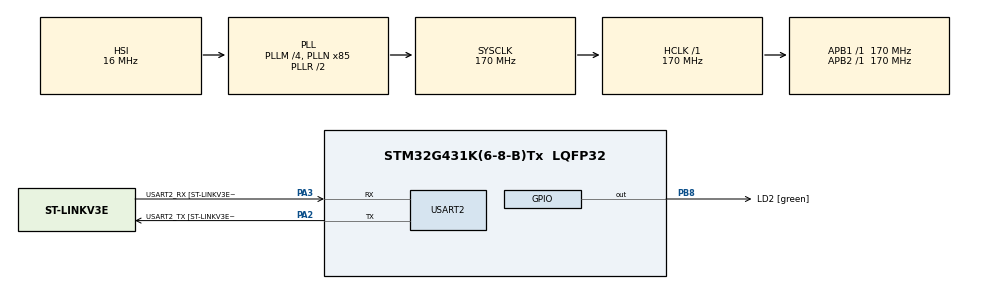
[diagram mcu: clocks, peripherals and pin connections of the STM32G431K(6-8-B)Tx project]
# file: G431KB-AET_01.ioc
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Mcu.Family=STM32G4
Mcu.Name=STM32G431K(6-8-B)Tx
Mcu.Package=LQFP32
NVIC.PriorityGroup=NVIC_PRIORITYGROUP_4
PA13.GPIO_Label=T_SWDIO
PA13.Mode=Serial_Wire
PA13.Signal=SYS_JTMS-SWDIO
PA14.GPIO_Label=T_SWCLK
PA14.Mode=Serial_Wire
PA14.Signal=SYS_JTCK-SWCLK
PA2.GPIO_Label=USART2_TX [ST-LINKV3E_VCP_RX]
PA2.Mode=Asynchronous
PA2.Signal=USART2_TX
PA3.GPIO_Label=USART2_RX [ST-LINKV3E_VCP_TX]
PA3.Mode=Asynchronous
PA3.Signal=USART2_RX
PB3.GPIO_Label=T_SWO
PB3.Signal=SYS_JTDO-SWO
PB8-BOOT0.GPIO_Label=LD2 [green]
PB8-BOOT0.Signal=GPIO_Output
ProjectManager.HeapSize=0x200
ProjectManager.StackSize=0x400
ProjectManager.TargetToolchain=STM32CubeIDE
RCC.ADC12Freq_Value=170000000
RCC.AHBFreq_Value=170000000
RCC.APB1Freq_Value=170000000
RCC.APB1TimFreq_Value=170000000
RCC.APB2Freq_Value=170000000
RCC.APB2TimFreq_Value=170000000
RCC.CortexFreq_Value=170000000
RCC.EXTERNAL_CLOCK_VALUE=12288000
RCC.HCLKFreq_Value=170000000
RCC.HSE_VALUE=8000000
RCC.HSI48_VALUE=48000000
RCC.HSI_VALUE=16000000
RCC.LSE_VALUE=32768
RCC.PLLM=RCC_PLLM_DIV4
RCC.PLLN=85
RCC.SYSCLKFreq_VALUE=170000000
RCC.SYSCLKSource=RCC_SYSCLKSOURCE_PLLCLK
RCC.USBFreq_Value=170000000
RCC.VCOOutputFreq_Value=340000000
USART2.VirtualMode-Asynchronous=VM_ASYNC
USART2.WordLength=WORDLENGTH_8B
board=NUCLEO-G431KB

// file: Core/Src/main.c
/* USER CODE BEGIN Header */
/**
  ******************************************************************************
  * @file           : main.c
  * @brief          : Main program body
  ******************************************************************************
  * @attention
  *
  * Copyright (c) 2024 STMicroelectronics.
  * All rights reserved.
  *
  * This software is licensed under terms that can be found in the LICENSE file
  * in the root directory of this software component.
  * If no LICENSE file comes with this software, it is provided AS-IS.
  *
  ******************************************************************************
  */
/* USER CODE END Header */
#include "main.h"
#include "usart.h"
#include "gpio.h"

/* USER CODE BEGIN PTD */

typedef struct
{
	uint16_t	gain;
	uint16_t	accelXraw;
	uint16_t	accelYraw;
	uint16_t	accelZraw;
}__attribute__ ((packed)) uartPacketTD;

typedef union
{
	uartPacketTD	S;
	uint8_t			B[8];
}__attribute__ ((packed)) uartPacketTD_U;

/* USER CODE END PTD */

void SystemClock_Config(void);

/* USER CODE BEGIN 0 */

//	uartPacketTD	packet;

	uartPacketTD_U	packet;

/* USER CODE END 0 */

int main(void)
{

  /* USER CODE BEGIN 1 */

	packet.S.gain = 0x1;
	packet.S.accelXraw = 20;
	packet.S.accelYraw = 500;
	packet.S.accelZraw = 8000;

  /* USER CODE END 1 */

  /* MCU Configuration--------------------------------------------------------*/

  /* Reset of all peripherals, Initializes the Flash interface and the Systick. */
  HAL_Init();

  /* Configure the system clock */
  SystemClock_Config();

  /* Initialize all configured peripherals */
  MX_GPIO_Init();
  MX_USART2_UART_Init();
  /* USER CODE BEGIN 2 */

  HDR_MSG(  "\n\n\r");
  HDR_MSG(	" AET  - V%u \n\r", (unsigned int)PCBA_FIRMWARE_REV);
  HDR_MSG(	" STM32G431KB \n\r");
  HDR_MSG(	" Compiled: " __DATE__ " " __TIME__ "\n\r");
  HDR_MSG(	" Debug level: %u\n\r", DEBUG_LVL);
  HDR_MSG(  " Core clock:  %u Hz\n\r", (unsigned int)SystemCoreClock);

  ERROR("ERROR TEST\n\r");
  INFO("INFO TEST\n\r");
  TRACE("TRACE TEST\n\r");
  ISR_TRACE("ISR TRACE TEST\n\r");

  /* USER CODE END 2 */

  /* Infinite loop */
  while (1)
  {
	  HAL_Delay(1000);

	  HAL_UART_Transmit(&huart2, (uint8_t*)packet.B, 8, 1000);

//	  printf("A");
//	  fflush(stdout);
  }
}

void SystemClock_Config(void)
{
  RCC_OscInitTypeDef RCC_OscInitStruct = {0};
  RCC_ClkInitTypeDef RCC_ClkInitStruct = {0};

  /** Configure the main internal regulator output voltage
  */
  HAL_PWREx_ControlVoltageScaling(PWR_REGULATOR_VOLTAGE_SCALE1_BOOST);

  /** Initializes the RCC Oscillators according to the specified parameters
  * in the RCC_OscInitTypeDef structure.
  */
  RCC_OscInitStruct.OscillatorType = RCC_OSCILLATORTYPE_HSI;
  RCC_OscInitStruct.HSIState = RCC_HSI_ON;
  RCC_OscInitStruct.HSICalibrationValue = RCC_HSICALIBRATION_DEFAULT;
  RCC_OscInitStruct.PLL.PLLState = RCC_PLL_ON;
  RCC_OscInitStruct.PLL.PLLSource = RCC_PLLSOURCE_HSI;
  RCC_OscInitStruct.PLL.PLLM = RCC_PLLM_DIV4;
  RCC_OscInitStruct.PLL.PLLN = 85;
  RCC_OscInitStruct.PLL.PLLP = RCC_PLLP_DIV2;
  RCC_OscInitStruct.PLL.PLLQ = RCC_PLLQ_DIV2;
  RCC_OscInitStruct.PLL.PLLR = RCC_PLLR_DIV2;
  if (HAL_RCC_OscConfig(&RCC_OscInitStruct) != HAL_OK)
  {
    Error_Handler();
  }

  /** Initializes the CPU, AHB and APB buses clocks
  */
  RCC_ClkInitStruct.ClockType = RCC_CLOCKTYPE_HCLK|RCC_CLOCKTYPE_SYSCLK
                              |RCC_CLOCKTYPE_PCLK1|RCC_CLOCKTYPE_PCLK2;
  RCC_ClkInitStruct.SYSCLKSource = RCC_SYSCLKSOURCE_PLLCLK;
  RCC_ClkInitStruct.AHBCLKDivider = RCC_SYSCLK_DIV1;
  RCC_ClkInitStruct.APB1CLKDivider = RCC_HCLK_DIV1;
  RCC_ClkInitStruct.APB2CLKDivider = RCC_HCLK_DIV1;

  if (HAL_RCC_ClockConfig(&RCC_ClkInitStruct, FLASH_LATENCY_4) != HAL_OK)
  {
    Error_Handler();
  }
}

void Error_Handler(void)
{
  __disable_irq();
  while (1)
  {
  }
}
